# ET6801 register map
Vendor: ETMCU Inc.; File version: v0.0.1
CPU: CM7 r2p1, little endian, MPU, FPU, I-cache, D-cache, ITCM, DTCM, 4 interrupt priority bits
Registers are 32-bit, read-write, reset 0x0 unless marked. A register's access mark holds for its fields unless they carry their own. Offsets are from the block's base; [hi:lo] are bit positions.

## QEP0 — Provide an overview of the purpose and functionality of the peripheral: qep
Base 0x4010F000
Same registers: QEP1 0x40110000, QEP2 0x40111000, QEP3 0x40112000, QEP4 0x40113000, QEP5 0x40114000
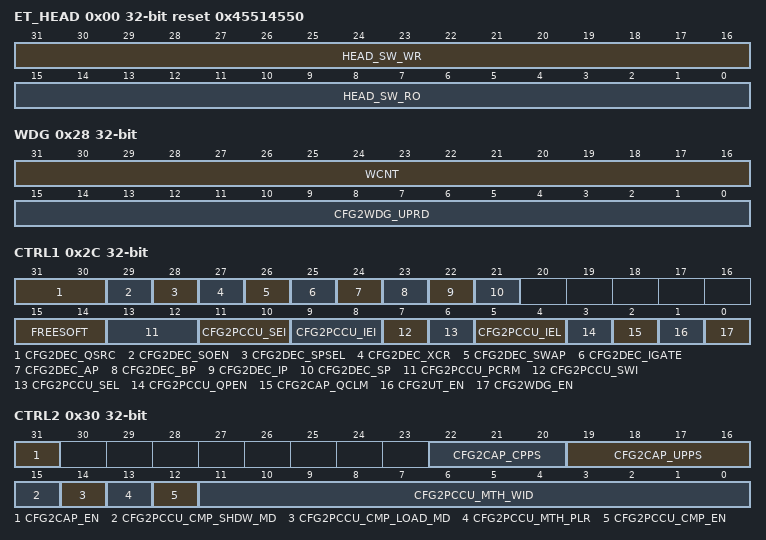
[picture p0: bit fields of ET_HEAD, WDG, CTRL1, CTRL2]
0x00 ET_HEAD reset 0x45514550
  [31:16] HEAD_SW_WR — 软件测试读写寄存器，硬件无访问
  [15:0] HEAD_SW_RO ro — 软件只读上报寄存器，硬件无访问，QEP的ASICII 码表示
0x04 POSCNT
  [31:0] POSCNT — 位置计数值，软件可配，硬件实时上报
0x08 POSINIT
  [31:0] CFG2PCCU_POSINIT — 位置计数初始值，特定事件来临后用此值初始化pcnt
0x0C POSMAX
  [31:0] CFG2PCCU_POSMAX — 位置计数最大值
0x10 POSCMP
  [31:0] CFG2PCCU_POSCMP — 位置比较值,生效值为该值+1；
0x14 POSILAT ro
  [31:0] PCCU2CFG_PCNTILAT — index事件触发的位置锁存值
0x18 POSSLAT ro
  [31:0] PCCU2CFG_PCNTSLAT — strobe事件触发位置锁存值
0x1C POSLAT ro
  [31:0] CAP2CFG_PCNTLAT — 超时位置锁存值
0x20 UTMR
  [31:0] UCNT — 计时单元计时值，软件可配置初始值
0x24 UPRD
  [31:0] CFG2UT_UPRD — 计时周期值
0x28 WDG
  [31:16] WCNT — 看门狗计时值，软件可配置初始值，硬件更新值进该寄存器
  [15:0] CFG2WDG_UPRD — 看门狗计数周期值，大于等于该值则送出中断
0x2C CTRL1
  [31:30] CFG2DEC_QSRC — 模式选择： 2'b00:QCLK = iCLK,QDIR = iDIR;(正交模式) 2'b01:QCLK = xCLK,QDIR = xDIR;（方向计数模式） 2'b10:QCLK = xCLK,QDIR = 1;（向上计数模式） 2'b11:QCLK = xCLK,QDIR = 0;（向下计数模式） 注：QCLK，QDIR代表DEC模块送出时钟及方向，iCLK代表经过解码后的，xCLK代表未经解码，同理对DIR；
  [29] CFG2DEC_SOEN — 匹配信号输出使能 0:不使能 1:使能
  [28] CFG2DEC_SPSEL — 匹配信号输出选择 0：index管脚输出 1：strobe管脚输出
  [27] CFG2DEC_XCR — 非正交模式下信号检测模式 0：双沿检测 1：仅上升沿检测
  [26] CFG2DEC_SWAP — 交换QEPA,QEPB信号使能 1：交换 0：不交换
  [25] CFG2DEC_IGATE — strobe门控index； 0：DEC最后输出的QI与QS无关； 1．DEC最后输出的QI与QS存在关系，QS存在必定存在QI； 注：该信号也就是将QI信号与QS信号联系起来了
  [24] CFG2DEC_AP — A输入取反使能 1：使能 0：不使能
  [23] CFG2DEC_BP — B输入取反使能 1：使能 0：不使能
  [22] CFG2DEC_IP — INDEX输入取反使能 1：使能 0：不使能
  [21] CFG2DEC_SP — STROBE输入取反使能 1：使能 0：不使能
  [15:14] FREESOFT — 仿真挂起时，内部计数的操作模式； 0：立即停止； 1：翻转停止 2：不影响计数 3：同2
  [13:12] CFG2PCCU_PCRM — pcnt的复位模式 2'b00: index复位； 2'b01:最值复位（无论处于哪种模式，都存在该复位模式）； 2'b10:第一次index复位，后同最值复位； 2'b11:超时复位；
  [11:10] CFG2PCCU_SEI — strobe事件初始化选择； 2'b00：不初始化 2'b01:不初始化 2'b10: strobe事件的上升沿初始化（不考虑方向）； 2'b11:QPOSCNT在输入的strobe上升沿初始化为QPOSINIT（正向），或在输入的strobe下降沿初始化为QPOSINIT（反向）；
  [9:8] CFG2PCCU_IEI — index事件初始化选择 2'b'10 : POSCNT在输入的INDEX上升沿初始化（不考虑正反向）； 2'b 11: POSCNT在输入的INDEX下降沿初始化(不考虑正反向）； 3.00或01为disable模式；
  [7] CFG2PCCU_SWI — 软件初始化（写该位为1的动作，并不是该寄存器为1）
  [6] CFG2PCCU_SEL — strobe事件锁存； 0：strobe的上升沿进行锁存（下降沿可通过将strobe取反变成上升沿）； 1：顺时针模式（正向）下，strobe上升沿；逆时针模式下（反向），strobe下降沿；
  [5:4] CFG2PCCU_IEL — index锁存模式； 2'b01:，在index上升沿锁存； 2'b10: 锁存发生在index的下降沿； 2'b11：标记锁存(待确定)；
  [3] CFG2PCCU_QPEN — 硬件操作pcnt 0：不可操作 1：可操作
  [2] CFG2CAP_QCLM — cap计数值锁存模式 0：cpu读取锁存； 1：超时锁存；
  [1] CFG2UT_EN — 计时器使能 0：不使能 1：使能
  [0] CFG2WDG_EN — 看门狗使能 0：不使能 1：使能
0x30 CTRL2
  [31] CFG2CAP_EN — 捕获模块使能 0：不使能 1：使能
  [22:20] CFG2CAP_CPPS — 捕获时钟分频系数(2^N) 0：1/1 1: 1/2 2: 1/4 ... 7:1/128
  [19:16] CFG2CAP_UPPS — qsign信号分频系数（2^N） 0：1/1 1: 1/2 2: 1/4 ... B:1/2048 C：reserved D：reserved E：reserved F：reserved reserved处理成1/2048分频；
  [15] CFG2PCCU_CMP_SHDW_MD — 是否为影子模式 0：非影子模式，配置比较值立刻更新 1：影子模式，配置比较值特定事件更新
  [14] CFG2PCCU_CMP_LOAD_MD — 影子模式下更新事件选择； 0：位置计数值为0后时更新； 1：位置计数值匹配后进行更新；
  [13] CFG2PCCU_MTH_PLR — 匹配信号是否取反输出 0：不取反 1：取反
  [12] CFG2PCCU_CMP_EN — 位置计数比较单元使能 0：不使能 1：使能
  [11:0] CFG2PCCU_MTH_WID — 位置匹配脉冲宽度； 生效值为（配置值+1）*4 个SYSYCLKOUT时钟；
0x34 INT_EN
  [11:0] INT_EN — 中断使能； 11：qmae（适配器检测到错误中断，即a，b同时出现有效电平） 10：uto（超时中断） 9: wto（看门狗中断） 8: pco（位置计数溢出中断） 7: pcu（位置计数下溢中断） 6：pcm（位置比较匹配中断） 5:pcr(位置比较ready中断) 4：iel（idnex锁存中断） 3：sel（strobe锁存中断） 2：pce（位置计数锁存错误中断） 1：phe（a、b相相位错误中断。即a，b相同时跳变） 0：qdc（正交模式下方向变化中断）
0x38 INT_MASK
  [11:0] INT_MASK — 1表示屏蔽逻辑中断;0 取消屏蔽
0x3C INT_FORCE_IND
  [11:0] INT_FORCE_IND — 1表示强制产生相应的测试中断，硬件自清零
0x40 INT_CLR
  [11:0] INT_CLR — 1表示清除相应的中断状态，硬件自清零
0x44 INT_RAW_RPT ro
  [11:0] INT_RAW_RPT — 中断MASK前RAW 中断状态上报
0x48 INT_STATUS_RPT ro
  [11:0] INT_STATUS_RPT — 中断MASK后中断状态上报
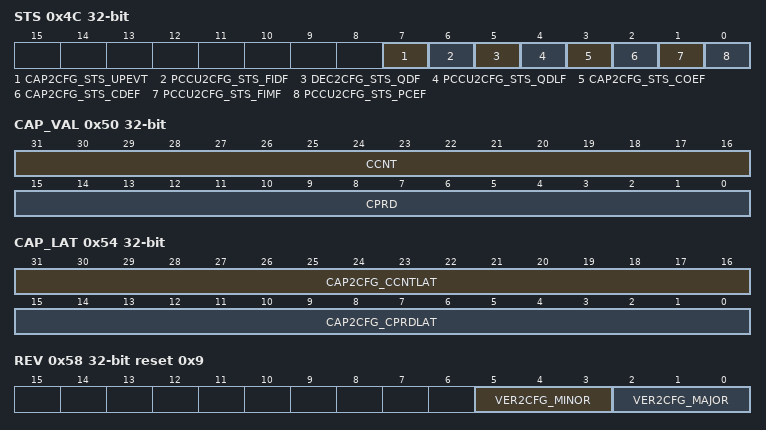
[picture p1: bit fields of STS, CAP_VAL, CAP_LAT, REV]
0x4C STS
  [7] CAP2CFG_STS_UPEVT — 锁存计时周期值成功标志,软件写1清
  [6] PCCU2CFG_STS_FIDF ro — 第一次index事件时的方向，仅在index复位模式下上报
  [5] DEC2CFG_STS_QDF ro — 实时更新的方向信息，仅在正交模式有效
  [4] PCCU2CFG_STS_QDLF ro — index标记事件来临更新方向信息，仅在index复位模式下上报，
  [3] CAP2CFG_STS_COEF — 计时值溢出上报，软件写1清
  [2] CAP2CFG_STS_CDEF — 存在方向变化上报，软件写1清
  [1] PCCU2CFG_STS_FIMF — 模式切换后标志第一次index来临，软件写1清
  [0] PCCU2CFG_STS_PCEF ro — 计数值错误上报，仅在index复位模式下产生，计数值一圈，内部计数值不符合预期错误
0x50 CAP_VAL
  [31:16] CCNT — 捕获模块计时值
  [15:0] CPRD — 捕获周期值
0x54 CAP_LAT ro
  [31:16] CAP2CFG_CCNTLAT — 捕获模块计时值锁存值
  [15:0] CAP2CFG_CPRDLAT — 捕获周期值锁存值
0x58 REV ro reset 0x9
  [5:3] VER2CFG_MINOR — 版本信息
  [2:0] VER2CFG_MAJOR — 版本信息
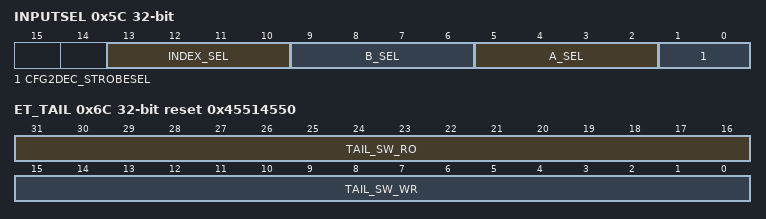
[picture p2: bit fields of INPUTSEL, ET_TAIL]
0x5C INPUTSEL
  [13:10] INDEX_SEL — eqep处理index选择配置； index = eqep_top_index_in[cfg_index_sel];其中输入的信号排布为： [15]~[9]:xbar2spwm_fault[6:0] [8]~[5]:cmpc_ctriph[3:0] [4]~[1]:cmpc_ctripl[3:0] [0]:device INDEX Pin
  [9:6] B_SEL — eqep处理B相输入选择配置； b = eqep_top_a_in[cfg_b_sel];其中输入的信号排布为： [15]~[9]:xbar2spwm_fault[6:0] [8]~[5]:cmpc_ctriph[3:0] [4]~[1]:cmpc_ctripl[3:0] [0]:device B Pin
  [5:2] A_SEL — eqep处理A相输入选择配置； a = eqep_top_a_in[cfg_a_sel],其中输入的信号排布为： [15]~[9]:xbar2spwm_fault[6:0] [8]~[5]:cmpc_ctriph[3:0] [4]~[1]:cmpc_ctripl[3:0] [0]:device A Pin
  [1:0] CFG2DEC_STROBESEL — Strobe信号源头选择逻辑； 2'b00,2'b01:选择管脚strobe信号； 2'b10:选择管脚信号或上spwm_adcsoca; 2'b11:选择管脚信号或上spwm_adcsocb;
0x60 QMACTRL
  [2:0] CFG2QMA_MODE — QMA模块运行模式； 000b：bypassed 001b:Mode1(QEPA，QEPB默认值为高模式)； 010b:Mode2(QEPA，QEPB默认值为低模式); other:bypassed(reserved);
0x6C ET_TAIL reset 0x45514550
  [31:16] TAIL_SW_RO ro — 软件只读硬件上报寄存器
  [15:0] TAIL_SW_WR — 软件测试读写寄存器，硬件无访问
